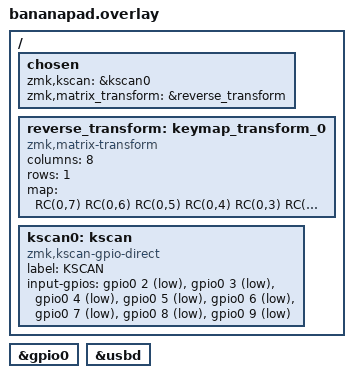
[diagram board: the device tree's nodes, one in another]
/*
 * Copyright (c) 2020 Pete Johanson, Ryan Cross
 *
 * SPDX-License-Identifier: MIT
 */

#include <dt-bindings/zmk/matrix_transform.h>

/ {
    chosen {
        zmk,kscan = &kscan0;
        zmk,matrix_transform = &reverse_transform;
    };

    reverse_transform: keymap_transform_0 {
        compatible = "zmk,matrix-transform";
        columns = <8>;
        rows = <1>;
        map = <RC(0,7) RC(0,6) RC(0,5) RC(0,4) RC(0,3) RC(0,2) RC(0,1) RC(0,0)>;
    };

    kscan0: kscan {
        compatible = "zmk,kscan-gpio-direct";
        label = "KSCAN";
        input-gpios
            = <&gpio0 2 (GPIO_ACTIVE_LOW | GPIO_PULL_UP)>
            , <&gpio0 3 (GPIO_ACTIVE_LOW | GPIO_PULL_UP)>
            , <&gpio0 4 (GPIO_ACTIVE_LOW | GPIO_PULL_UP)>
            , <&gpio0 5 (GPIO_ACTIVE_LOW | GPIO_PULL_UP)>
            , <&gpio0 6 (GPIO_ACTIVE_LOW | GPIO_PULL_UP)>
            , <&gpio0 7 (GPIO_ACTIVE_LOW | GPIO_PULL_UP)>
            , <&gpio0 8 (GPIO_ACTIVE_LOW | GPIO_PULL_UP)>
            , <&gpio0 9 (GPIO_ACTIVE_LOW | GPIO_PULL_UP)>
            ;
    };
};

&gpio0 {
    status = "okay";
};

&usbd {
    status = "okay";
};
